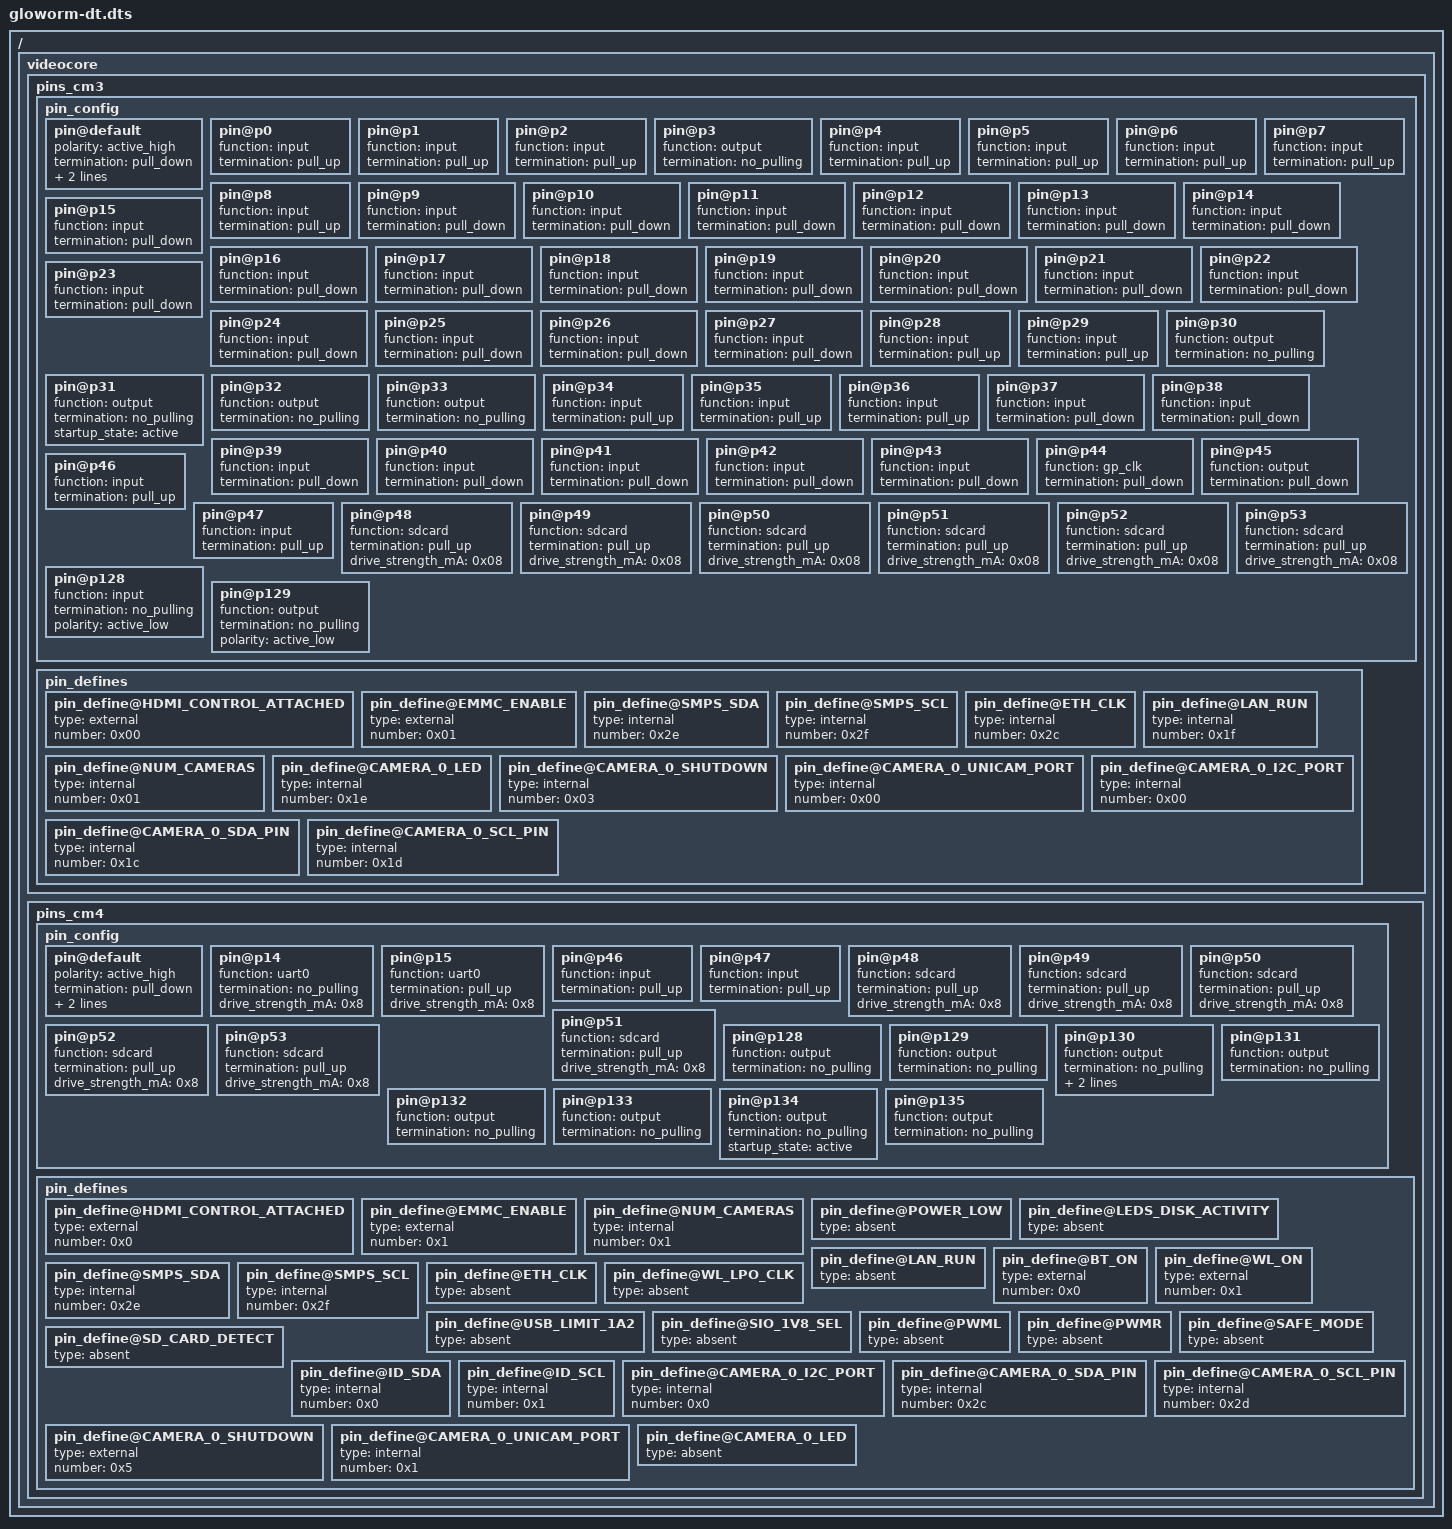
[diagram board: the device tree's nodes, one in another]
/dts-v1/;
/ {
	videocore {
		pins_cm3 {
			pin_config {
				pin@default {
					polarity = "active_high";
					termination = "pull_down";
					startup_state = "inactive";
					function = "input";
				};

				pin@p0 {
					function = "input";
					termination = "pull_up";
				};

				pin@p1 {
					function = "input";
					termination = "pull_up";
				};

				pin@p2 {
					function = "input";
					termination = "pull_up";
				};

				pin@p3 {
					function = "output";
					termination = "no_pulling";
				};

				pin@p4 {
					function = "input";
					termination = "pull_up";
				};

				pin@p5 {
					function = "input";
					termination = "pull_up";
				};

				pin@p6 {
					function = "input";
					termination = "pull_up";
				};

				pin@p7 {
					function = "input";
					termination = "pull_up";
				};

				pin@p8 {
					function = "input";
					termination = "pull_up";
				};

				pin@p9 {
					function = "input";
					termination = "pull_down";
				};

				pin@p10 {
					function = "input";
					termination = "pull_down";
				};

				pin@p11 {
					function = "input";
					termination = "pull_down";
				};

				pin@p12 {
					function = "input";
					termination = "pull_down";
				};

				pin@p13 {
					function = "input";
					termination = "pull_down";
				};

				pin@p14 {
					function = "input";
					termination = "pull_down";
				};

				pin@p15 {
					function = "input";
					termination = "pull_down";
				};

				pin@p16 {
					function = "input";
					termination = "pull_down";
				};

				pin@p17 {
					function = "input";
					termination = "pull_down";
				};

				pin@p18 {
					function = "input";
					termination = "pull_down";
				};

				pin@p19 {
					function = "input";
					termination = "pull_down";
				};

				pin@p20 {
					function = "input";
					termination = "pull_down";
				};

				pin@p21 {
					function = "input";
					termination = "pull_down";
				};

				pin@p22 {
					function = "input";
					termination = "pull_down";
				};

				pin@p23 {
					function = "input";
					termination = "pull_down";
				};

				pin@p24 {
					function = "input";
					termination = "pull_down";
				};

				pin@p25 {
					function = "input";
					termination = "pull_down";
				};

				pin@p26 {
					function = "input";
					termination = "pull_down";
				};

				pin@p27 {
					function = "input";
					termination = "pull_down";
				};

				pin@p28 {
					function = "input";
					termination = "pull_up";
				};

				pin@p29 {
					function = "input";
					termination = "pull_up";
				};

				pin@p30 {
					function = "output";
					termination = "no_pulling";
				};

				pin@p31 {
					function = "output";
					termination = "no_pulling";
					startup_state = "active";
				};

				pin@p32 {
					function = "output";
					termination = "no_pulling";
				};

				pin@p33 {
					function = "output";
					termination = "no_pulling";
				};

				pin@p34 {
					function = "input";
					termination = "pull_up";
				};

				pin@p35 {
					function = "input";
					termination = "pull_up";
				};

				pin@p36 {
					function = "input";
					termination = "pull_up";
				};

				pin@p37 {
					function = "input";
					termination = "pull_down";
				};

				pin@p38 {
					function = "input";
					termination = "pull_down";
				};

				pin@p39 {
					function = "input";
					termination = "pull_down";
				};

				pin@p40 {
					function = "input";
					termination = "pull_down";
				};

				pin@p41 {
					function = "input";
					termination = "pull_down";
				};

				pin@p42 {
					function = "input";
					termination = "pull_down";
				};

				pin@p43 {
					function = "input";
					termination = "pull_down";
				};

				pin@p44 {
					function = "gp_clk";
					termination = "pull_down";
				};

				pin@p45 {
					function = "output";
					termination = "pull_down";
				};

				pin@p46 {
					function = "input";
					termination = "pull_up";
				};

				pin@p47 {
					function = "input";
					termination = "pull_up";
				};

				pin@p48 {
					function = "sdcard";
					termination = "pull_up";
					drive_strength_mA = <0x08>;
				};

				pin@p49 {
					function = "sdcard";
					termination = "pull_up";
					drive_strength_mA = <0x08>;
				};

				pin@p50 {
					function = "sdcard";
					termination = "pull_up";
					drive_strength_mA = <0x08>;
				};

				pin@p51 {
					function = "sdcard";
					termination = "pull_up";
					drive_strength_mA = <0x08>;
				};

				pin@p52 {
					function = "sdcard";
					termination = "pull_up";
					drive_strength_mA = <0x08>;
				};

				pin@p53 {
					function = "sdcard";
					termination = "pull_up";
					drive_strength_mA = <0x08>;
				};

				pin@p128 {
					function = "input";
					termination = "no_pulling";
					polarity = "active_low";
				};

				pin@p129 {
					function = "output";
					termination = "no_pulling";
					polarity = "active_low";
				};
			};

			pin_defines {
				pin_define@HDMI_CONTROL_ATTACHED {
					type = "external";
					number = <0x00>;
				};

				pin_define@EMMC_ENABLE {
					type = "external";
					number = <0x01>;
				};

				pin_define@SMPS_SDA {
					type = "internal";
					number = <0x2e>;
				};

				pin_define@SMPS_SCL {
					type = "internal";
					number = <0x2f>;
				};

				pin_define@ETH_CLK {
					type = "internal";
					number = <0x2c>;
				};

				pin_define@LAN_RUN {
					type = "internal";
					number = <0x1f>;
				};

				pin_define@NUM_CAMERAS {
					type = "internal";
					number = <0x01>;
				};

				pin_define@CAMERA_0_LED {
					type = "internal";
					number = <0x1e>;
				};

				pin_define@CAMERA_0_SHUTDOWN {
					type = "internal";
					number = <0x03>;
				};

				pin_define@CAMERA_0_UNICAM_PORT {
					type = "internal";
					number = <0x00>;
				};

				pin_define@CAMERA_0_I2C_PORT {
					type = "internal";
					number = <0x00>;
				};

				pin_define@CAMERA_0_SDA_PIN {
					type = "internal";
					number = <0x1c>;
				};

				pin_define@CAMERA_0_SCL_PIN {
					type = "internal";
					number = <0x1d>;
				};
			};
		};

		pins_cm4 {

			pin_config {

				pin@default {
					polarity = "active_high";
					termination = "pull_down";
					startup_state = "inactive";
					function = "input";
				};

				pin@p14 {
					function = "uart0";
					termination = "no_pulling";
					drive_strength_mA = <0x8>;
				};

				pin@p15 {
					function = "uart0";
					termination = "pull_up";
					drive_strength_mA = <0x8>;
				};

				pin@p46 {
					function = "input";
					termination = "pull_up";
				};

				pin@p47 {
					function = "input";
					termination = "pull_up";
				};

				pin@p48 {
					function = "sdcard";
					termination = "pull_up";
					drive_strength_mA = <0x8>;
				};

				pin@p49 {
					function = "sdcard";
					termination = "pull_up";
					drive_strength_mA = <0x8>;
				};

				pin@p50 {
					function = "sdcard";
					termination = "pull_up";
					drive_strength_mA = <0x8>;
				};

				pin@p51 {
					function = "sdcard";
					termination = "pull_up";
					drive_strength_mA = <0x8>;
				};

				pin@p52 {
					function = "sdcard";
					termination = "pull_up";
					drive_strength_mA = <0x8>;
				};

				pin@p53 {
					function = "sdcard";
					termination = "pull_up";
					drive_strength_mA = <0x8>;
				};

				pin@p128 {
					function = "output";
					termination = "no_pulling";
				};

				pin@p129 {
					function = "output";
					termination = "no_pulling";
				};

				pin@p130 {
					function = "output";
					termination = "no_pulling";
					polarity = "active_low";
					startup_state = "active";
				};

				pin@p131 {
					function = "output";
					termination = "no_pulling";
				};

				pin@p132 {
					function = "output";
					termination = "no_pulling";
				};

				pin@p133 {
					function = "output";
					termination = "no_pulling";
				};

				pin@p134 {
					function = "output";
					termination = "no_pulling";
					startup_state = "active";
				};

				pin@p135 {
					function = "output";
					termination = "no_pulling";
				};
			};

			pin_defines {

				pin_define@HDMI_CONTROL_ATTACHED {
					type = "external";
					number = <0x0>;
				};

				pin_define@EMMC_ENABLE {
					type = "external";
					number = <0x1>;
				};

				pin_define@NUM_CAMERAS {
					type = "internal";
					number = <0x1>;
				};

				pin_define@POWER_LOW {
					type = "absent";
				};

				pin_define@LEDS_DISK_ACTIVITY {
					type = "absent";
				};

				pin_define@LAN_RUN {
					type = "absent";
				};

				pin_define@BT_ON {
					type = "external";
					number = <0x0>;
				};

				pin_define@WL_ON {
					type = "external";
					number = <0x1>;
				};

				pin_define@SMPS_SDA {
					type = "internal";
					number = <0x2e>;
				};

				pin_define@SMPS_SCL {
					type = "internal";
					number = <0x2f>;
				};

				pin_define@ETH_CLK {
					type = "absent";
				};

				pin_define@WL_LPO_CLK {
					type = "absent";
				};

				pin_define@USB_LIMIT_1A2 {
					type = "absent";
				};

				pin_define@SIO_1V8_SEL {
					type = "absent";
				};

				pin_define@PWML {
					type = "absent";
				};

				pin_define@PWMR {
					type = "absent";
				};

				pin_define@SAFE_MODE {
					type = "absent";
				};

				pin_define@SD_CARD_DETECT {
					type = "absent";
				};

				pin_define@ID_SDA {
					type = "internal";
					number = <0x0>;
				};

				pin_define@ID_SCL {
					type = "internal";
					number = <0x1>;
				};

				pin_define@CAMERA_0_I2C_PORT {
					type = "internal";
					number = <0x0>;
				};

				pin_define@CAMERA_0_SDA_PIN {
					type = "internal";
					number = <0x2c>;
				};

				pin_define@CAMERA_0_SCL_PIN {
					type = "internal";
					number = <0x2d>;
				};

				pin_define@CAMERA_0_SHUTDOWN {
					type = "external";
					number = <0x5>;
				};

				pin_define@CAMERA_0_UNICAM_PORT {
					type = "internal";
					number = <0x1>;
				};

				pin_define@CAMERA_0_LED {
					type = "absent";
				};
			};
		};

	};
};
